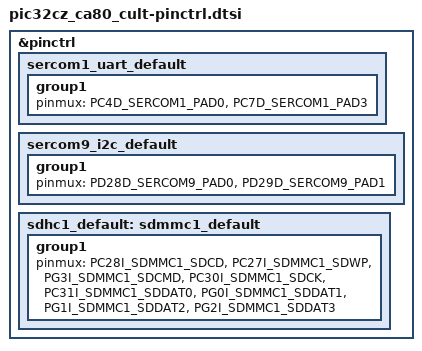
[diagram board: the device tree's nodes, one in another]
/*
 * Copyright (c) 2026 Microchip Technology Inc.
 *
 * SPDX-License-Identifier: Apache-2.0
 */

#include <dt-bindings/pic32c/pic32cz_ca/pic32cz_ca80/pic32cz8110ca80208-pinctrl.h>

&pinctrl {
	sercom1_uart_default: sercom1_uart_default {
		group1 {
			pinmux = <PC4D_SERCOM1_PAD0>,
				 <PC7D_SERCOM1_PAD3>;
		};
	};

	sercom9_i2c_default: sercom9_i2c_default {
		group1 {
			pinmux = <PD28D_SERCOM9_PAD0>,
				 <PD29D_SERCOM9_PAD1>;
		};
	};

	sdhc1_default: sdmmc1_default {
		group1 {
			pinmux = <PC28I_SDMMC1_SDCD>,
				 <PC27I_SDMMC1_SDWP>,
				 <PG3I_SDMMC1_SDCMD>,
				 <PC30I_SDMMC1_SDCK>,
				 <PC31I_SDMMC1_SDDAT0>,
				 <PG0I_SDMMC1_SDDAT1>,
				 <PG1I_SDMMC1_SDDAT2>,
				 <PG2I_SDMMC1_SDDAT3>;
		};
	};
};
